VERSION ""

NS_ :

BS_:

BU_:

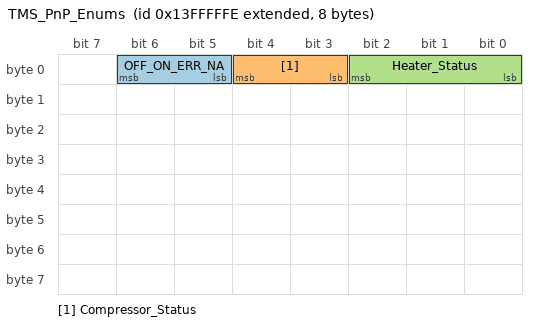
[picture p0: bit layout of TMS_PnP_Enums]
BO_ 2483027966 TMS_PnP_Enums: 8 Vector__XXX
 SG_ OFF_ON_ERR_NA : 5|2@1+ (1,0) [0|3] "" Vector__XXX
 SG_ Compressor_Status : 3|2@1+ (1,0) [0|3] "" Vector__XXX
 SG_ Heater_Status : 0|3@1+ (1,0) [0|4] "" Vector__XXX

BO_ 2415919102 BattPack_Humidity: 24 Vector__XXX
 SG_ SensValue_1 : 182|10@1+ (0.1,0) [0|100] "%" Vector__XXX
 SG_ SensValue_2 : 172|10@1+ (0.1,0) [0|100] "%" Vector__XXX
 SG_ SensValue_3 : 162|10@1+ (0.1,0) [0|100] "%" Vector__XXX
 SG_ SensValue_4 : 152|10@1+ (0.1,0) [0|100] "%" Vector__XXX
 SG_ SensValue_5 : 142|10@1+ (0.1,0) [0|100] "%" Vector__XXX
 SG_ SensValue_6 : 132|10@1+ (0.1,0) [0|100] "%" Vector__XXX
 SG_ SensValue_7 : 122|10@1+ (0.1,0) [0|100] "%" Vector__XXX
 SG_ SensValue_8 : 112|10@1+ (0.1,0) [0|100] "%" Vector__XXX
 SG_ SensValue_9 : 102|10@1+ (0.1,0) [0|100] "%" Vector__XXX
 SG_ SensValue_10 : 92|10@1+ (0.1,0) [0|100] "%" Vector__XXX
 SG_ SensValue_11 : 82|10@1+ (0.1,0) [0|100] "%" Vector__XXX
 SG_ SensValue_12 : 72|10@1+ (0.1,0) [0|100] "%" Vector__XXX
 SG_ SensValue_13 : 62|10@1+ (0.1,0) [0|100] "%" Vector__XXX
 SG_ SensValue_14 : 52|10@1+ (0.1,0) [0|100] "%" Vector__XXX
 SG_ SensValue_15 : 42|10@1+ (0.1,0) [0|100] "%" Vector__XXX
 SG_ SensValue_16 : 32|10@1+ (0.1,0) [0|100] "%" Vector__XXX
 SG_ SensorStatus_1 : 30|2@1+ (1,0) [0|3] "" Vector__XXX
 SG_ SensorStatus_2 : 28|2@1+ (1,0) [0|3] "" Vector__XXX
 SG_ SensorStatus_3 : 26|2@1+ (1,0) [0|3] "" Vector__XXX
 SG_ SensorStatus_4 : 24|2@1+ (1,0) [0|3] "" Vector__XXX
 SG_ SensorStatus_5 : 22|2@1+ (1,0) [0|3] "" Vector__XXX
 SG_ SensorStatus_6 : 20|2@1+ (1,0) [0|3] "" Vector__XXX
 SG_ SensorStatus_7 : 18|2@1+ (1,0) [0|3] "" Vector__XXX
 SG_ SensorStatus_8 : 16|2@1+ (1,0) [0|3] "" Vector__XXX
 SG_ SensorStatus_9 : 14|2@1+ (1,0) [0|3] "" Vector__XXX
 SG_ SensorStatus_10 : 12|2@1+ (1,0) [0|3] "" Vector__XXX
 SG_ SensorStatus_11 : 10|2@1+ (1,0) [0|3] "" Vector__XXX
 SG_ SensorStatus_12 : 8|2@1+ (1,0) [0|3] "" Vector__XXX
 SG_ SensorStatus_13 : 6|2@1+ (1,0) [0|3] "" Vector__XXX
 SG_ SensorStatus_14 : 4|2@1+ (1,0) [0|3] "" Vector__XXX
 SG_ SensorStatus_15 : 2|2@1+ (1,0) [0|3] "" Vector__XXX
 SG_ SensorStatus_16 : 0|2@1+ (1,0) [0|3] "" Vector__XXX

BO_ 2550136830 TMS_PnP_Signals: 9 Vector__XXX
 SG_ FloatSignal_Range : 56|16@1+ (0.1,-3276.8) [-3276.8|3276.7] "" Vector__XXX
 SG_ Temperature : 40|10@1+ (0.25,-40) [-40|215.75] "degC" Vector__XXX
 SG_ uint8Signal : 32|8@1+ (1,0) [0|255] "" Vector__XXX
 SG_ BoolSignal : 50|1@1+ (1,0) [0|0] "" Vector__XXX
 SG_ Int16Signal : 16|16@1+ (1,-32768) [-32768|32767] "" Vector__XXX
 SG_ FloatSignal : 0|16@1+ (0.1,-3276.8) [-3276.8|3276.7] "" Vector__XXX

CM_ "$File: //depot/auto/dbc/EtalonMessages/TMS/0.1.0.0/TMS_etalon.dbc $
$Change: 215781 $
$DateTime: 2024/08/14 10:30:58 $
$Revision: #1 $";
BA_DEF_ SG_  "SigType" ENUM  "Default","Range","RangeSigned","ASCII","Discrete","Control","ReferencePGN","DTC","StringDelimiter","StringLength","StringLengthControl","MessageCounter","MessageChecksum";
BA_DEF_ SG_  "GenSigEVName" STRING ;
BA_DEF_ SG_  "GenSigILSupport" ENUM  "No","Yes";
BA_DEF_ SG_  "GenSigSendType" ENUM  "Cyclic","OnWrite","OnWriteWithRepetition","OnChange","OnChangeWithRepetition","IfActive","IfActiveWithRepetition","NoSigSendType";
BA_DEF_ SG_  "GenSigStartValue" INT 0 2147483647;
BA_DEF_ BO_  "GenMsgILSupport" ENUM  "No","Yes";
BA_DEF_ BU_  "NmStationAddress" INT 0 255;
BA_DEF_ BO_  "GenMsgSendType" ENUM  "cyclic","NotUsed","IfActive","NotUsed","NotUsed","NotUsed","NotUsed","NotUsed","noMsgSendType";
BA_DEF_ BO_  "GenMsgRequestable" INT 0 1;
BA_DEF_ BO_  "GenMsgCycleTime" INT 0 3600000;
BA_DEF_ SG_  "SPN" INT 0 524287;
BA_DEF_  "DBName" STRING ;
BA_DEF_  "BusType" STRING ;
BA_DEF_  "ProtocolType" STRING ;
BA_DEF_ BO_  "VFrameFormat" ENUM  "StandardCAN","ExtendedCAN","reserved","J1939PG";
BA_DEF_DEF_  "SigType" "Default";
BA_DEF_DEF_  "GenSigEVName" "Env@Nodename_@Signame";
BA_DEF_DEF_  "GenSigILSupport" "Yes";
BA_DEF_DEF_  "GenSigSendType" "NoSigSendType";
BA_DEF_DEF_  "GenSigStartValue" 0;
BA_DEF_DEF_  "GenMsgILSupport" "Yes";
BA_DEF_DEF_  "NmStationAddress" 254;
BA_DEF_DEF_  "GenMsgSendType" "noMsgSendType";
BA_DEF_DEF_  "GenMsgRequestable" 1;
BA_DEF_DEF_  "GenMsgCycleTime" 0;
BA_DEF_DEF_  "SPN" 0;
BA_DEF_DEF_  "DBName" "";
BA_DEF_DEF_  "BusType" "CAN";
BA_DEF_DEF_  "ProtocolType" "J1939";
BA_DEF_DEF_  "VFrameFormat" "J1939PG";
BA_ "DBName" "TMS_etalon";
BA_ "GenMsgCycleTime" BO_ 2483027966 100;
BA_ "GenMsgSendType" BO_ 2483027966 0;
BA_ "GenMsgSendType" BO_ 2415919102 0;
BA_ "GenMsgCycleTime" BO_ 2415919102 500;
BA_ "GenMsgCycleTime" BO_ 2550136830 100;
BA_ "GenMsgSendType" BO_ 2550136830 0;
BA_ "GenSigStartValue" SG_ 2483027966 OFF_ON_ERR_NA 3;
BA_ "GenSigStartValue" SG_ 2415919102 SensorStatus_1 3;
BA_ "GenSigStartValue" SG_ 2415919102 SensorStatus_2 3;
BA_ "GenSigStartValue" SG_ 2415919102 SensorStatus_3 3;
BA_ "GenSigStartValue" SG_ 2415919102 SensorStatus_4 3;
BA_ "GenSigStartValue" SG_ 2415919102 SensorStatus_5 3;
BA_ "GenSigStartValue" SG_ 2415919102 SensorStatus_6 3;
BA_ "GenSigStartValue" SG_ 2415919102 SensorStatus_7 3;
BA_ "GenSigStartValue" SG_ 2415919102 SensorStatus_8 3;
BA_ "GenSigStartValue" SG_ 2415919102 SensorStatus_9 3;
BA_ "GenSigStartValue" SG_ 2415919102 SensorStatus_10 3;
BA_ "GenSigStartValue" SG_ 2415919102 SensorStatus_11 3;
BA_ "GenSigStartValue" SG_ 2415919102 SensorStatus_12 3;
BA_ "GenSigStartValue" SG_ 2415919102 SensorStatus_13 3;
BA_ "GenSigStartValue" SG_ 2415919102 SensorStatus_14 3;
BA_ "GenSigStartValue" SG_ 2415919102 SensorStatus_15 3;
BA_ "GenSigStartValue" SG_ 2415919102 SensorStatus_16 3;
BA_ "SigType" SG_ 2550136830 FloatSignal_Range 1;
VAL_ 2483027966 OFF_ON_ERR_NA 3 "Not Available" 2 "Error" 1 "On" 0 "Off" ;
VAL_ 2483027966 Compressor_Status 3 "NA" 2 "Power_Limit" 1 "On" 0 "Off" ;
VAL_ 2483027966 Heater_Status 7 "NA" 5 "Production_Mode" 4 "Operation" 3 "PermanentLock" 2 "OverheatLock" 1 "TemporaryLock" 0 "Off" ;
VAL_ 2415919102 SensorStatus_1 0 "NotUsed" 1 "OK" 2 "Error" 3 "CommFault" ;
VAL_ 2415919102 SensorStatus_2 0 "NotUsed" 1 "OK" 2 "Error" 3 "CommFault" ;
VAL_ 2415919102 SensorStatus_3 0 "NotUsed" 1 "OK" 2 "Error" 3 "CommFault" ;
VAL_ 2415919102 SensorStatus_4 0 "NotUsed" 1 "OK" 2 "Error" 3 "CommFault" ;
VAL_ 2415919102 SensorStatus_5 0 "NotUsed" 1 "OK" 2 "Error" 3 "CommFault" ;
VAL_ 2415919102 SensorStatus_6 0 "NotUsed" 1 "OK" 2 "Error" 3 "CommFault" ;
VAL_ 2415919102 SensorStatus_7 0 "NotUsed" 1 "OK" 2 "Error" 3 "CommFault" ;
VAL_ 2415919102 SensorStatus_8 0 "NotUsed" 1 "OK" 2 "Error" 3 "CommFault" ;
VAL_ 2415919102 SensorStatus_9 0 "NotUsed" 1 "OK" 2 "Error" 3 "CommFault" ;
VAL_ 2415919102 SensorStatus_10 0 "NotUsed" 1 "OK" 2 "Error" 3 "CommFault" ;
VAL_ 2415919102 SensorStatus_11 0 "NotUsed" 1 "OK" 2 "Error" 3 "CommFault" ;
VAL_ 2415919102 SensorStatus_12 0 "NotUsed" 1 "OK" 2 "Error" 3 "CommFault" ;
VAL_ 2415919102 SensorStatus_13 0 "NotUsed" 1 "OK" 2 "Error" 3 "CommFault" ;
VAL_ 2415919102 SensorStatus_14 0 "NotUsed" 1 "OK" 2 "Error" 3 "CommFault" ;
VAL_ 2415919102 SensorStatus_15 0 "NotUsed" 1 "OK" 2 "Error" 3 "CommFault" ;
VAL_ 2415919102 SensorStatus_16 0 "NotUsed" 1 "OK" 2 "Error" 3 "CommFault" ;
